# STM32N645 register map
File version: 1.0
CPU: CM55 r0p1, little endian, no MPU, FPU, vendor SysTick, 8 interrupt priority bits
Registers are 32-bit, read-write, reset 0x0 unless marked. A register's access mark holds for its fields unless they carry their own. Offsets are from the block's base; [hi:lo] are bit positions.

## ADC12 — ADC common registers
Base 0x40022300
Same registers: ADC12_S 0x50022300
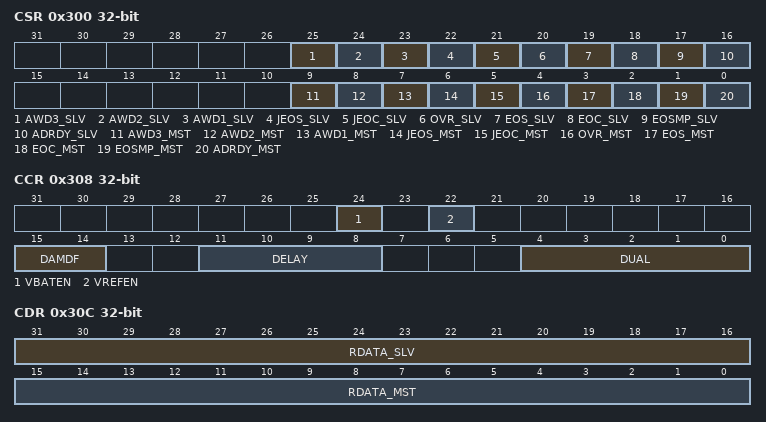
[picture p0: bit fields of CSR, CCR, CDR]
0x300 CSR ro — ADC12 common status register
  [25] AWD3_SLV — Analog watchdog 3 flag of the slave ADC
  [24] AWD2_SLV — Analog watchdog 2 flag of the slave ADC
  [23] AWD1_SLV — Analog watchdog 1 flag of the slave ADC
  [22] JEOS_SLV — End of injected sequence flag of the slave ADC
  [21] JEOC_SLV — End of injected conversion flag of the slave ADC
  [20] OVR_SLV — Overrun flag of the slave ADC
  [19] EOS_SLV — End of regular sequence flag of the slave ADC. This bit is a copy of the EOS bit in the corresponding ADC_ISR register.
  [18] EOC_SLV — End of regular conversion of the slave ADC
  [17] EOSMP_SLV — End of Sampling phase flag of the slave ADC
  [16] ADRDY_SLV — Slave ADC ready
  [9] AWD3_MST — Analog watchdog 3 flag of the master ADC
  [8] AWD2_MST — Analog watchdog 2 flag of the master ADC
  [7] AWD1_MST — Analog watchdog 1 flag of the master ADC
  [6] JEOS_MST — End of injected sequence flag of the master ADC
  [5] JEOC_MST — End of injected conversion flag of the master ADC
  [4] OVR_MST — Overrun flag of the master ADC
  [3] EOS_MST — End of regular sequence flag of the master ADC
  [2] EOC_MST — End of regular conversion of the master ADC
  [1] EOSMP_MST — End of Sampling phase flag of the master ADC
  [0] ADRDY_MST — Master ADC ready
0x308 CCR — ADC12 common control register
  [24] VBATEN — VBAT enable
  [22] VREFEN — V less than sub>REFINT less than /sub> enable
  [15:14] DAMDF — Dual ADC mode data format
  [11:8] DELAY — Delay between two sampling phases
  [4:0] DUAL — Dual ADC mode selection
0x30C CDR ro — ADC12 common regular data register for Dual mode
  [31:16] RDATA_SLV — Regular data of the slave ADC
  [15:0] RDATA_MST — Regular data of the master ADC.
0x310 CDR2 ro — ADC12 common regular data register for Dual mode
  [31:0] RDATA_ALT — Regular data of the master/slave alternated ADCs.

## CACHEAXI — AXI cache
Base 0x480DFC00
Same registers: CACHEAXI_S 0x580DFC00
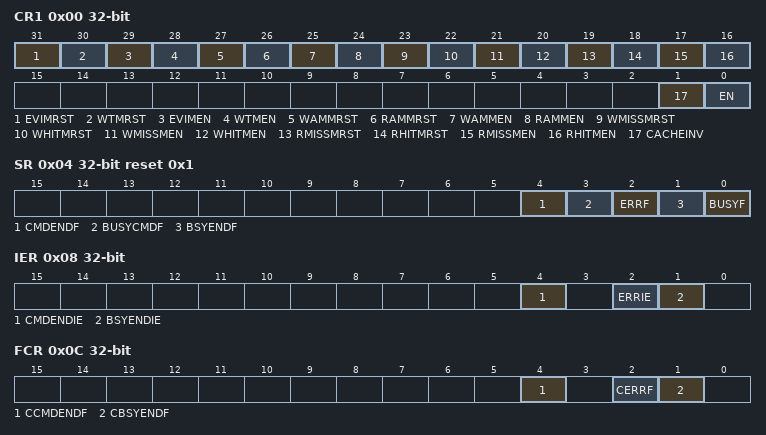
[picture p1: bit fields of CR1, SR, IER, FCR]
0x00 CR1 access per field — CACHEAXI control register 1
  [31] EVIMRST wo — eviction monitor reset
  [30] WTMRST wo — write-through monitor reset
  [29] EVIMEN rw — eviction monitor enable
  [28] WTMEN rw — write-through monitor enable
  [27] WAMMRST wo — write-allocate miss monitor reset
  [26] RAMMRST wo — read-allocate miss monitor reset
  [25] WAMMEN rw — write-allocate miss monitor enable
  [24] RAMMEN rw — read-allocate miss monitor enable
  [23] WMISSMRST wo — write-miss monitor reset
  [22] WHITMRST wo — write-hit monitor reset
  [21] WMISSMEN rw — write-miss monitor enable
  [20] WHITMEN rw — write-hit monitor enable
  [19] RMISSMRST wo — read-miss monitor reset
  [18] RHITMRST wo — read-hit monitor reset
  [17] RMISSMEN rw — read-miss monitor enable
  [16] RHITMEN rw — read-hit monitor enable
  [1] CACHEINV wo — full cache invalidation
  [0] EN rw — enable
0x04 SR ro reset 0x1 — CACHEAXI status register
  [4] CMDENDF — command end flag
  [3] BUSYCMDF — command busy flag
  [2] ERRF — cache error flag
  [1] BSYENDF — full invalidate busy end flag
  [0] BUSYF — full invalidate busy flag
0x08 IER — CACHEAXI interrupt enable register
  [4] CMDENDIE — interrupt enable on command end
  [2] ERRIE — interrupt enable on cache error
  [1] BSYENDIE — interrupt enable on busy end
0x0C FCR wo — CACHEAXI flag clear register
  [4] CCMDENDF — clear command end flag
  [2] CERRF — clear cache error flag
  [1] CBSYENDF — clear full invalidate busy end flag
0x10 RHMONR ro — CACHEAXI read-hit monitor register
  [31:0] RHITMON — cache read-hit monitor counter
0x14 RMMONR ro — CACHEAXI read-miss monitor register
  [31:0] RMISSMON — cache read-miss monitor counter
0x18 RAMMONR ro — CACHEAXI read-allocate miss monitor register
  [31:0] RAMMON — cache read-allocate miss monitor counter
0x1C EVIMONR ro — CACHEAXI eviction monitor register
  [31:0] EVIMON — cache eviction monitor counter
0x20 WHMONR ro — CACHEAXI write-hit monitor register
  [31:0] WHITMON — cache write-hit monitor counter
0x24 WMMONR ro — CACHEAXI write-miss monitor register
  [31:0] WMISSMON — cache write-miss monitor counter
0x28 WAMMONR ro — CACHEAXI write-allocate miss monitor register
  [31:0] WAMMON — cache write-allocate miss monitor counter
0x2C WTMONR ro — CACHEAXI write-through monitor register
  [31:0] WTMON — cache write-through monitor counter
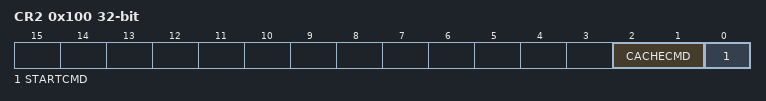
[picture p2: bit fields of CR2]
0x100 CR2 access per field — CACHEAXI control register 2
  [2:1] CACHECMD rw — cache command maintenance operation (clean or clean-and-invalidate an address range)
  [0] STARTCMD wo — starts maintenance range command (maintenance operation defined in CACHECMD).
0x104 CMDRSADDRR — CACHEAXI command range start address register
  [31:6] CMDSTARTADDR — start address of range to which the cache maintenance command specified in CACHEAXI_CR2.CACHECMD field applies
0x108 CMDREADDRR — CACHEAXI command range end address register
  [31:6] CMDENDADDR — end address of range to which the cache maintenance command specified in CACHEAXI_CR2.CACHECMD field applies
